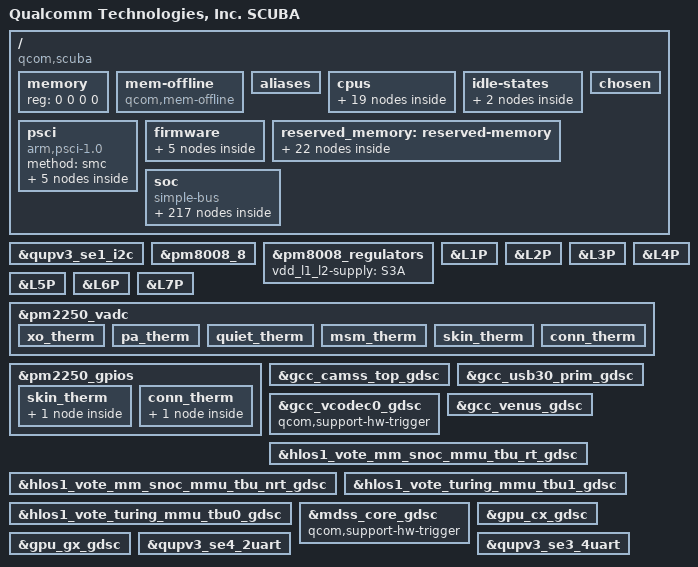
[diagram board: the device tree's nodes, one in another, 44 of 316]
#include <dt-bindings/interrupt-controller/arm-gic.h>
#include <dt-bindings/interconnect/qcom,icc.h>
#include <dt-bindings/interconnect/qcom,scuba.h>
#include <dt-bindings/clock/qcom,dispcc-scuba.h>
#include <dt-bindings/clock/qcom,gcc-scuba.h>
#include <dt-bindings/clock/qcom,gpucc-scuba.h>
#include <dt-bindings/spmi/spmi.h>
#include <dt-bindings/clock/qcom,rpmcc.h>
#include <dt-bindings/regulator/qcom,rpmh-regulator-levels.h>
#include <dt-bindings/gpio/gpio.h>
#include <dt-bindings/soc/qcom,dcc_v2.h>

/ {
	model = "Qualcomm Technologies, Inc. SCUBA";
	compatible = "qcom,scuba";
	qcom,msm-id = <441 0x10000>;
	interrupt-parent = <&intc>;

	#address-cells = <2>;
	#size-cells = <2>;
	memory { device_type = "memory"; reg = <0 0 0 0>; };

	mem-offline {
		compatible = "qcom,mem-offline";
		offline-sizes = <0x1 0x40000000 0x0 0x40000000>,
				<0x1 0xc0000000 0x0 0x80000000>,
				<0x2 0xc0000000 0x1 0x40000000>;
		granule = <512>;
	};

	aliases: aliases {
		mmc0 = &sdhc_1; /* SDC1 eMMC slot */
		mmc1 = &sdhc_2; /* SDC2 SD Card slot */
		serial0 = &qupv3_se4_2uart;
		hsuart0 = &qupv3_se3_4uart;
	};

	cpus {
		#address-cells = <2>;
		#size-cells = <0>;

		CPU0: cpu@0 {
			device_type = "cpu";
			compatible = "arm,armv8";
			reg = <0x0 0x0>;
			cpu-idle-states = <&SILVER_OFF>;
			power-domains = <&CPU_PD0>;
			power-domain-names = "psci";
			enable-method = "psci";
			capacity-dmips-mhz = <1024>;
			dynamic-power-coefficient = <100>;
			next-level-cache = <&L2_0>;
			qcom,freq-domain = <&cpufreq_hw 0 4>;
			qcom,lmh-dcvs = <&lmh_dcvs0>;
			#cooling-cells = <2>;
			L2_0: l2-cache {
				compatible = "arm,arch-cache";
				cache-level = <2>;
			};

			L1_I_0: l1-icache {
				compatible = "arm,arch-cache";
			};

			L1_D_0: l1-dcache {
				compatible = "arm,arch-cache";
			};
		};

		CPU1: cpu@1 {
			device_type = "cpu";
			compatible = "arm,armv8";
			reg = <0x0 0x1>;
			cpu-idle-states = <&SILVER_OFF>;
			power-domains = <&CPU_PD1>;
			power-domain-names = "psci";
			enable-method = "psci";
			capacity-dmips-mhz = <1024>;
			dynamic-power-coefficient = <100>;
			next-level-cache = <&L2_0>;
			qcom,freq-domain = <&cpufreq_hw 0 4>;
			qcom,lmh-dcvs = <&lmh_dcvs0>;

			L1_I_1: l1-icache {
				compatible = "arm,arch-cache";
			};

			L1_D_1: l1-dcache {
				compatible = "arm,arch-cache";
			};
		};

		CPU2: cpu@2 {
			device_type = "cpu";
			compatible = "arm,armv8";
			reg = <0x0 0x2>;
			cpu-idle-states = <&SILVER_OFF>;
			power-domains = <&CPU_PD2>;
			power-domain-names = "psci";
			enable-method = "psci";
			capacity-dmips-mhz = <1024>;
			dynamic-power-coefficient = <100>;
			next-level-cache = <&L2_0>;
			qcom,freq-domain = <&cpufreq_hw 0 4>;
			qcom,lmh-dcvs = <&lmh_dcvs0>;

			L1_I_2: l1-icache {
				compatible = "arm,arch-cache";
			};

			L1_D_2: l1-dcache {
				compatible = "arm,arch-cache";
			};
		};

		CPU3: cpu@3 {
			device_type = "cpu";
			compatible = "arm,armv8";
			reg = <0x0 0x3>;
			cpu-idle-states = <&SILVER_OFF>;
			power-domains = <&CPU_PD3>;
			power-domain-names = "psci";
			enable-method = "psci";
			capacity-dmips-mhz = <1024>;
			dynamic-power-coefficient = <100>;
			next-level-cache = <&L2_0>;
			qcom,freq-domain = <&cpufreq_hw 0 4>;
			qcom,lmh-dcvs = <&lmh_dcvs0>;

			L1_I_3: l1-icache {
				compatible = "arm,arch-cache";
			};

			L1_D_3: l1-dcache {
				compatible = "arm,arch-cache";
			};
		};

		cpu-map {
			cluster0 {
				core0 {
					cpu = <&CPU0>;
				};

				core1 {
					cpu = <&CPU1>;
				};

				core2 {
					cpu = <&CPU2>;
				};

				core3 {
					cpu = <&CPU3>;
				};
			};
		};
	};

	idle-states {
		SILVER_OFF: silver-c3 {  /* C3 */
			compatible = "arm,idle-state";
			idle-state-name = "pc";
			entry-latency-us = <297>;
			exit-latency-us = <324>;
			min-residency-us = <1110>;
			arm,psci-suspend-param = <0x40000003>;
			local-timer-stop;
		};

		SILVER_CLUSTER_D3: silver-cluster-d3 { /* D3 */
			compatible = "domain-idle-state";
			idle-state-name = "pwr-l2-pc";
			entry-latency-us = <800>;
			exit-latency-us = <2118>;
			min-residency-us = <7376>;
			arm,psci-suspend-param = <0x41000043>;
		};
	};

	psci {
		compatible = "arm,psci-1.0";
		method = "smc";

		CPU_PD0: cpu-pd0 {
			#power-domain-cells = <0>;
			power-domains = <&CLUSTER_PD>;
		};

		CPU_PD1: cpu-pd1 {
			#power-domain-cells = <0>;
			power-domains = <&CLUSTER_PD>;
		};

		CPU_PD2: cpu-pd2 {
			#power-domain-cells = <0>;
			power-domains = <&CLUSTER_PD>;
		};

		CPU_PD3: cpu-pd3 {
			#power-domain-cells = <0>;
			power-domains = <&CLUSTER_PD>;
		};

		CLUSTER_PD: cluster-pd0 {
			#power-domain-cells = <0>;
			domain-idle-states = <&SILVER_CLUSTER_D3>;
		};
	};

	firmware: firmware {
		qcom_scm {
			compatible = "qcom,scm";
			qcom,dload-mode = <&tcsr 0x13000>;
		};

		android {
			compatible = "android,firmware";
			vbmeta {
				compatible="android,vbmeta";
				parts = "vbmeta,boot,system,vendor,dtbo,recovery";
			};

			fstab {
				compatible = "android,fstab";
				vendor {
					compatible = "android,vendor";
					dev = "/dev/block/platform/soc/4744000.sdhci/by-name/vendor";
					type = "ext4";
					mnt_flags = "ro,barrier=1,discard";
					fsmgr_flags = "wait,slotselect,avb";
					status = "ok";
				};
			};
		};
	};

	reserved_memory: reserved-memory {
		#address-cells = <2>;
		#size-cells = <2>;
		ranges;

		hyp_region: hyp_region@45700000 {
			no-map;
			reg = <0x0 0x45700000 0x0 0x600000>;
		};

		xbl_aop_mem: xbl_aop_mem@45e00000 {
			no-map;
			reg = <0x0 0x45e00000 0x0 0x100000>;
		};

		sec_apps_mem: sec_apps_region@45fff000 {
			no-map;
			reg = <0x0 0x45fff000 0x0 0x1000>;
		};

		smem_region: smem@46000000 {
			no-map;
			reg = <0x0 0x46000000 0x0 0x200000>;
		};

		pil_modem_mem: modem_region@4ab00000 {
			no-map;
			reg = <0x0 0x4ab00000 0x0 0x6900000>;
		};

		wlan_msa_mem: wlan_msa_region@51900000 {
			no-map;
			reg = <0x0 0x51900000 0x0 0x100000>;
		};

		pil_adsp_mem: adsp_regions@51a00000 {
			no-map;
			reg = <0x0 0x51a00000 0x0 0x1c00000>;
		};

		pil_ipa_fw_mem: ips_fw_region@53600000 {
			no-map;
			reg = <0x0 0x53600000 0x0 0x10000>;
		};

		pil_ipa_gsi_mem: ipa_gsi_region@53610000 {
			no-map;
			reg = <0x0 0x53610000 0x0 0x5000>;
		};

		pil_gpu_mem: gpu_region@53615000 {
			no-map;
			reg = <0x0 0x53615000 0x0 0x2000>;
		};

		video_mem: video_region@53617000 {
			no-map;
			reg = <0x0 0x53617000 0x0 0x700000>;
		};

		removed_region: removed_region@60000000 {
			no-map;
			reg = <0x0 0x60000000 0x0 0x3900000>;
		};

		adsp_mem: adsp_region {
			compatible = "shared-dma-pool";
			alloc-ranges = <0 0x00000000 0 0xffffffff>;
			reusable;
			alignment = <0 0x400000>;
			size = <0 0x800000>;
		};

		dump_mem: mem_dump_region {
			compatible = "shared-dma-pool";
			alloc-ranges = <0x0 0x00000000 0x0 0xffffffff>;
			reusable;
			size = <0 0x800000>;
		};

		secure_display_memory: secure_display_region {
			compatible = "shared-dma-pool";
			alloc-ranges = <0 0x00000000 0 0xffffffff>;
			reusable;
			alignment = <0 0x400000>;
			size = <0 0x5c00000>;
		};

		non_secure_display_memory: non_secure_display_region {
			compatible = "shared-dma-pool";
			reusable;
			alloc-ranges = <0x0 0x00000000 0x0 0xffffffff>;
			size = <0x0 0xa400000>;
			alignment = <0x0 0x400000>;
		};

		qseecom_mem: qseecom_region {
			compatible = "shared-dma-pool";
			alloc-ranges = <0x0 0x00000000 0x0 0xffffffff>;
			reusable;
			alignment = <0x0 0x400000>;
			size = <0x0 0x1400000>;
		};

		qseecom_ta_mem: qseecom_ta_region {
			compatible = "shared-dma-pool";
			alloc-ranges = <0x0 0x00000000 0x0 0xffffffff>;
			reusable;
			alignment = <0x0 0x400000>;
			size = <0x0 0x1000000>;
		};

		ramoops_mem: ramoops_region {
			compatible = "ramoops";
			alloc-ranges = <0x0 0x00000000 0xffffffff 0xffffffff>;
			size = <0x0 0x200000>;
			pmsg-size = <0x200000>;
			mem-type = <2>;
		};

		audio_cma_mem: audio_cma_region {
			compatible = "shared-dma-pool";
			alloc-ranges = <0x0 0x00000000 0x0 0xffffffff>;
			reusable;
			alignment = <0x0 0x400000>;
			size = <0x0 0x1C00000>;
		};

		/* global autoconfigured region for contiguous allocations */
		system_cma: linux,cma {
			compatible = "shared-dma-pool";
			alloc-ranges = <0x0 0x00000000 0x0 0xffffffff>;
			reusable;
			alignment = <0x0 0x400000>;
			size = <0x0 0x2000000>;
			linux,cma-default;
		};

		va_md_mem: va_md_mem_region {
			compatible = "shared-dma-pool";
			alloc-ranges = <0x0 0x00000000 0x0 0xffffffff>;
			reusable;
			size = <0x0 0x1000000>;
		};
	};

	chosen {
		bootargs = "lpm_levels.sleep_disabled=1 console=ttyMSM0,115200n8 msm_rtb.filter=0x237 service_locator.enable=1 swiotlb=2048 loop.max_part=7 cpufreq.default_governor=performance rcupdate.rcu_expedited=1 rcu_nocbs=0-7 kpti=off export_pmu_events movable_node ftrace_dump_on_oops disable_dma32=on cgroup.memory=nokmem,nosocket panic=5";
	};

	soc: soc { };
};

&soc {
	#address-cells = <1>;
	#size-cells = <1>;
	ranges = <0 0 0 0xffffffff>;
	compatible = "simple-bus";

	slimbam: bamdma@a584000 {
		compatible = "qcom,bam-v1.7.0";
		reg = <0xa584000 0x20000>, <0xa66f000 0x1000>;
		reg-names = "bam", "bam_remote_mem";
		#dma-cells = <1>;
		interrupts = <GIC_SPI 284 IRQ_TYPE_LEVEL_HIGH>;
		qcom,controlled-remotely;
		num-channels  = <31>;
		qcom,ee = <1>;
		qcom,num-ees = <2>;
	};

	slim_msm: slim@a5c0000 {
		compatible = "qcom,slim-ngd-v1.5.0";
		reg = <0xa5c0000 0x2c000>, <0xa66e000 0x1000>;
		reg-names = "ctrl", "slimbus_remote_mem";
		#address-cells = <1>;
		#size-cells = <0>;
		interrupts = <GIC_SPI 283 IRQ_TYPE_LEVEL_HIGH>;
		qcom,apps-ch-pipes = <0x0>;
		qcom,ea-pc = <0x360>;
		dmas = <&slimbam 3>, <&slimbam 4>;
		dma-names = "rx", "tx";
		status = "disabled";
	};

	intc: interrupt-controller@f200000 {
		compatible = "arm,gic-v3";
		#interrupt-cells = <3>;
		interrupt-controller;
		interrupt-parent = <&intc>;
		#redistributor-regions = <1>;
		redistributor-stride = <0x0 0x20000>;
		reg = <0xf200000 0x10000>,     /* GICD */
		      <0xf300000 0x100000>;    /* GICR * 8 */
		interrupts = <1 9 4>;
	};

	mpm: interrupt-controller@0x45f01b8 {
		compatible = "qcom,mpm", "qcom,mpm-scuba";
		interrupts = <GIC_SPI 197 IRQ_TYPE_EDGE_RISING>;
		reg = <0x45f01b8 0x1000>,
		      <0xf111008 0x4>,  /* MSM_APCS_GCC_BASE 4K */
		      <0xf121000 0x1000>;
		reg-names = "vmpm", "ipc", "timer";
		qcom,num-mpm-irqs = <96>;
		interrupt-controller;
		interrupt-parent = <&intc>;
		#interrupt-cells = <2>;
	};

	jtag_mm0: jtagmm@9040000 {
		compatible = "qcom,jtagv8-mm";
		reg = <0x9040000 0x1000>;
		reg-names = "etm-base";

		clocks = <&rpmcc RPM_SMD_QDSS_CLK>;
		clock-names = "core_clk";

		qcom,coresight-jtagmm-cpu = <&CPU0>;
	};

	jtag_mm1: jtagmm@9140000 {
		compatible = "qcom,jtagv8-mm";
		reg = <0x9140000 0x1000>;
		reg-names = "etm-base";

		clocks = <&rpmcc RPM_SMD_QDSS_CLK>;
		clock-names = "core_clk";

		qcom,coresight-jtagmm-cpu = <&CPU1>;
	};

	jtag_mm2: jtagmm@9240000 {
		compatible = "qcom,jtagv8-mm";
		reg = <0x9240000 0x1000>;
		reg-names = "etm-base";

		clocks = <&rpmcc RPM_SMD_QDSS_CLK>;
		clock-names = "core_clk";

		qcom,coresight-jtagmm-cpu = <&CPU2>;
	};

	jtag_mm3: jtagmm@9340000 {
		compatible = "qcom,jtagv8-mm";
		reg = <0x9340000 0x1000>;
		reg-names = "etm-base";

		clocks = <&rpmcc RPM_SMD_QDSS_CLK>;
		clock-names = "core_clk";

		qcom,coresight-jtagmm-cpu = <&CPU3>;
	};

	timer {
		compatible = "arm,armv8-timer";
		interrupts = <1 1 0xf08>,
			     <1 2 0xf08>,
			     <1 3 0xf08>,
			     <1 0 0xf08>;
		clock-frequency = <19200000>;
	};

	dcc: dcc_v2@1be2000 {
		compatible = "qcom,dcc-v2";
		reg = <0x1be2000 0x1000>,
			<0x1bee000 0x2000>;
		reg-names = "dcc-base", "dcc-ram-base";
		dcc-ram-offset = <0x2000>;

		link_list1 {
			qcom,curr-link-list = <3>;
			qcom,data-sink = "sram";
			qcom,link-list = <DCC_READ 0x0f1880b4 1 0>,
				<DCC_READ 0x0f1980b4 1 0>,
				<DCC_READ 0x0f1a80b4 1 0>,
				<DCC_READ 0x0f1b80b4 1 0>,
				<DCC_READ 0x0f1d1228 1 0>,
				<DCC_READ 0x4488100 1 0>,
				<DCC_READ 0x4488400 2 0>,
				<DCC_READ 0x4488410 1 0>,
				<DCC_READ 0x4488420 2 0>,
				<DCC_READ 0x4488430 2 0>,
				<DCC_READ 0x448c100 1 0>,
				<DCC_READ 0x448c400 2 0>,
				<DCC_READ 0x448c410 1 0>,
				<DCC_READ 0x448c420 2 0>,
				<DCC_READ 0x448c430 2 0>,
				<DCC_READ 0x4490100 1 0>,
				<DCC_READ 0x4490400 2 0>,
				<DCC_READ 0x4490410 1 0>,
				<DCC_READ 0x4490420 2 0>,
				<DCC_READ 0x4490430 2 0>,
				<DCC_READ 0x4494100 1 0>,
				<DCC_READ 0x4494400 2 0>,
				<DCC_READ 0x4494410 1 0>,
				<DCC_READ 0x4494420 2 0>,
				<DCC_READ 0x4494430 2 0>,
				<DCC_READ 0x449810c 1 0>,
				<DCC_READ 0x4498400 2 0>,
				<DCC_READ 0x4498410 1 0>,
				<DCC_READ 0x4498420 2 0>,
				<DCC_READ 0x4498430 2 0>,
				<DCC_READ 0x44a0100 1 0>,
				<DCC_READ 0x44a0400 2 0>,
				<DCC_READ 0x44a0410 1 0>,
				<DCC_READ 0x44a0420 2 0>,
				<DCC_READ 0x44a0430 2 0>,
				<DCC_READ 0x44b0560 1 0>,
				<DCC_READ 0x44b05a0 1 0>,
				<DCC_READ 0x44b1800 1 0>,
				<DCC_READ 0x44b408c 1 0>,
				<DCC_READ 0x44b409c 1 0>,
				<DCC_READ 0x44b0520 1 0>,
				<DCC_READ 0x44b5070 2 0>,
				<DCC_READ 0x44bc220 1 0>,
				<DCC_READ 0x44bc400 7 0>,
				<DCC_READ 0x44bc420 9 0>,
				<DCC_READ 0x44bd800 1 0>,
				<DCC_READ 0x44c5800 1 0>,
				<DCC_READ 0x4480040 2 0>,
				<DCC_READ 0x4480810 2 0>,
				<DCC_READ 0x44b0a40 1 0>,
				<DCC_READ 0x4506044 1 0>,
				<DCC_READ 0x45061dc 1 0>,
				<DCC_READ 0x45061ec 1 0>,
				<DCC_READ 0x4506028 2 0>,
				<DCC_READ 0x4506094 1 0>,
				<DCC_READ 0x4506608 1 0>,
				<DCC_READ 0x447d02c 4 0>,
				<DCC_READ 0x447d040 1 0>,
				<DCC_READ 0x450002c 2 0>,
				<DCC_READ 0x4500094 1 0>,
				<DCC_READ 0x450009c 1 0>,
				<DCC_READ 0x45000c4 2 0>,
				<DCC_READ 0x45003dc 1 0>,
				<DCC_READ 0x45005d8 1 0>,
				<DCC_READ 0x450102c 2 0>,
				<DCC_READ 0x4501094 1 0>,
				<DCC_READ 0x450109c 1 0>,
				<DCC_READ 0x45010c4 2 0>,
				<DCC_READ 0x45013dc 1 0>,
				<DCC_READ 0x45015d8 1 0>,
				<DCC_READ 0x450202c 2 0>,
				<DCC_READ 0x4502094 1 0>,
				<DCC_READ 0x450209c 1 0>,
				<DCC_READ 0x45020c4 2 0>,
				<DCC_READ 0x45023dc 1 0>,
				<DCC_READ 0x45025d8 1 0>,
				<DCC_READ 0x450302c 2 0>,
				<DCC_READ 0x4503094 1 0>,
				<DCC_READ 0x450309c 1 0>,
				<DCC_READ 0x45030c4 2 0>,
				<DCC_READ 0x45033dc 1 0>,
				<DCC_READ 0x45035d8 1 0>,
				<DCC_READ 0x450402c 2 0>,
				<DCC_READ 0x4504094 1 0>,
				<DCC_READ 0x450409c 1 0>,
				<DCC_READ 0x45040c8 2 0>,
				<DCC_READ 0x45043dc 1 0>,
				<DCC_READ 0x45045d8 1 0>,
				<DCC_READ 0x450502c 2 0>,
				<DCC_READ 0x4505094 1 0>,
				<DCC_READ 0x450509c 1 0>,
				<DCC_READ 0x45050c4 2 0>,
				<DCC_READ 0x45053dc 1 0>,
				<DCC_READ 0x45055d8 1 0>,
				<DCC_READ 0x1900010 1 0>,
				<DCC_READ 0x1900020 1 0>,
				<DCC_READ 0x1900024 1 0>,
				<DCC_READ 0x1900028 1 0>,
				<DCC_READ 0x190002c 1 0>,
				<DCC_READ 0x1900030 1 0>,
				<DCC_READ 0x1900034 1 0>,
				<DCC_READ 0x1900038 1 0>,
				<DCC_READ 0x190003c 1 0>,
				<DCC_READ 0x1900240 1 0>,
				<DCC_READ 0x1900244 1 0>,
				<DCC_READ 0x1900248 1 0>,
				<DCC_READ 0x190024c 1 0>,
				<DCC_READ 0x1900250 1 0>,
				<DCC_READ 0x1900258 1 0>,
				<DCC_READ 0x1900290 1 0>,
				<DCC_READ 0x1900300 1 0>,
				<DCC_READ 0x1900304 1 0>,
				<DCC_READ 0x1900308 1 0>,
				<DCC_READ 0x190030c 1 0>,
				<DCC_READ 0x1900310 1 0>,
				<DCC_READ 0x1900314 1 0>,
				<DCC_READ 0x1900318 1 0>,
				<DCC_READ 0x1900900 1 0>,
				<DCC_READ 0x1900904 1 0>,
				<DCC_READ 0x1900d00 1 0>,
				<DCC_READ 0x1909100 1 0>,
				<DCC_READ 0x1909104 1 0>,
				<DCC_READ 0x44b0120 1 0>,
				<DCC_READ 0x44b0124 1 0>,
				<DCC_READ 0x44b0128 1 0>,
				<DCC_READ 0x44b012c 1 0>,
				<DCC_READ 0x44b0130 1 0>,
				<DCC_READ 0x44b0100 1 0>,
				<DCC_READ 0x44b0020 1 0>,
				<DCC_READ 0x44c4000 1 0>,
				<DCC_READ 0x44c4020 1 0>,
				<DCC_READ 0x44c4030 1 0>,
				<DCC_READ 0x44c4100 1 0>,
				<DCC_READ 0x44c410c 1 0>,
				<DCC_READ 0x44c4400 1 0>,
				<DCC_READ 0x44c4410 1 0>,
				<DCC_READ 0x44c4420 1 0>,
				<DCC_READ 0x1411004 1 0>,
				<DCC_READ 0x1411028 1 0>,
				<DCC_READ 0x1458004 1 0>,
				<DCC_READ 0x1880108 1 0>,
				<DCC_READ 0x1880110 1 0>,
				<DCC_READ 0x1880120 1 0>,
				<DCC_READ 0x1880124 1 0>,
				<DCC_READ 0x1880128 1 0>,
				<DCC_READ 0x188012c 1 0>,
				<DCC_READ 0x1880130 1 0>,
				<DCC_READ 0x1880134 1 0>,
				<DCC_READ 0x1880138 1 0>,
				<DCC_READ 0x188013c 1 0>,
				<DCC_READ 0x1880240 1 0>,
				<DCC_READ 0x1880248 1 0>,
				<DCC_READ 0x1880290 1 0>,
				<DCC_READ 0x1880300 1 0>,
				<DCC_READ 0x1880304 1 0>,
				<DCC_READ 0x1880308 1 0>,
				<DCC_READ 0x188030c 1 0>,
				<DCC_READ 0x1880310 1 0>,
				<DCC_READ 0x1880314 1 0>,
				<DCC_READ 0x1880318 1 0>,
				<DCC_READ 0x188031c 1 0>,
				<DCC_READ 0x1880700 1 0>,
				<DCC_READ 0x1880704 1 0>,
				<DCC_READ 0x1880708 1 0>,
				<DCC_READ 0x188070c 1 0>,
				<DCC_READ 0x1880710 1 0>,
				<DCC_READ 0x1880714 1 0>,
				<DCC_READ 0x1880718 1 0>,
				<DCC_READ 0x188071c 1 0>,
				<DCC_READ 0x1881100 1 0>,
				<DCC_READ 0x1881104 1 0>,
				<DCC_READ 0xf112000 1 0>,
				<DCC_READ 0xf11200c 1 0>,
				<DCC_READ 0xf112c0c 1 0>,
				<DCC_READ 0xf112c10 1 0>,
				<DCC_READ 0xf112c20 1 0>,
				<DCC_READ 0xf1b9000 1 0>,
				<DCC_READ 0xf1b900c 1 0>,
				<DCC_READ 0xf1b9c0c 1 0>,
				<DCC_READ 0xf1b9c10 1 0>,
				<DCC_READ 0xf1b9c18 1 0>,
				<DCC_READ 0xf1a9000 1 0>,
				<DCC_READ 0xf1a900c 1 0>,
				<DCC_READ 0xf1a9c0c 1 0>,
				<DCC_READ 0xf1a9c10 1 0>,
				<DCC_READ 0xf1a9c20 1 0>,
				<DCC_READ 0xf199000 1 0>,
				<DCC_READ 0xf19900c 1 0>,
				<DCC_READ 0xf199c0c 1 0>,
				<DCC_READ 0xf199c10 1 0>,
				<DCC_READ 0xf199c20 1 0>,
				<DCC_READ 0xf189000 1 0>,
				<DCC_READ 0xf18900c 1 0>,
				<DCC_READ 0xf189c0c 1 0>,
				<DCC_READ 0xf189c10 1 0>,
				<DCC_READ 0xf189c20 1 0>,
				<DCC_READ 0xf111014 1 0>,
				<DCC_READ 0xf111018 1 0>,
				<DCC_READ 0xf111218 1 0>,
				<DCC_READ 0xf111234 1 0>,
				<DCC_READ 0xf111264 1 0>,
				<DCC_READ 0xf111290 1 0>,
				<DCC_READ 0x0f521700 1 0>,
				<DCC_READ 0x0f112c18 1 0>,
				<DCC_READ 0x0f513a84 1 0>,
				<DCC_READ 0x01b60110 1 0>,
				<DCC_READ 0x1400000 1 0>,
				<DCC_READ 0x1400004 1 0>,
				<DCC_READ 0x1400008 1 0>,
				<DCC_READ 0x1400010 1 0>,
				<DCC_READ 0x1400014 1 0>,
				<DCC_READ 0x1400018 1 0>,
				<DCC_READ 0x1400020 1 0>,
				<DCC_READ 0x1400024 1 0>,
				<DCC_READ 0x1401000 1 0>,
				<DCC_READ 0x1401004 1 0>,
				<DCC_READ 0x1401008 1 0>,
				<DCC_READ 0x1401010 1 0>,
				<DCC_READ 0x1401014 1 0>,
				<DCC_READ 0x1401018 1 0>,
				<DCC_READ 0x1401020 1 0>,
				<DCC_READ 0x1401024 1 0>,
				<DCC_READ 0x1402000 1 0>,
				<DCC_READ 0x1402004 1 0>,
				<DCC_READ 0x1402008 1 0>,
				<DCC_READ 0x1402010 1 0>,
				<DCC_READ 0x1402014 1 0>,
				<DCC_READ 0x1402018 1 0>,
				<DCC_READ 0x1402020 1 0>,
				<DCC_READ 0x1402024 1 0>,
				<DCC_READ 0x1403000 1 0>,
				<DCC_READ 0x1403004 1 0>,
				<DCC_READ 0x1403008 1 0>,
				<DCC_READ 0x1403010 1 0>,
				<DCC_READ 0x1403014 1 0>,
				<DCC_READ 0x1403018 1 0>,
				<DCC_READ 0x1403020 1 0>,
				<DCC_READ 0x1403024 1 0>,
				<DCC_READ 0x1404000 1 0>,
				<DCC_READ 0x1404004 1 0>,
				<DCC_READ 0x1404008 1 0>,
				<DCC_READ 0x1404010 1 0>,
				<DCC_READ 0x1404014 1 0>,
				<DCC_READ 0x1404018 1 0>,
				<DCC_READ 0x1404020 1 0>,
				<DCC_READ 0x1404024 1 0>,
				<DCC_READ 0x1405000 1 0>,
				<DCC_READ 0x1405004 1 0>,
				<DCC_READ 0x1405008 1 0>,
				<DCC_READ 0x1405010 1 0>,
				<DCC_READ 0x1405014 1 0>,
				<DCC_READ 0x1405018 1 0>,
				<DCC_READ 0x1405020 1 0>,
				<DCC_READ 0x1405024 1 0>,
				<DCC_READ 0x1406000 1 0>,
				<DCC_READ 0x1406004 1 0>,
				<DCC_READ 0x1406008 1 0>,
				<DCC_READ 0x1406010 1 0>,
				<DCC_READ 0x1406014 1 0>,
				<DCC_READ 0x1406018 1 0>,
				<DCC_READ 0x1406020 1 0>,
				<DCC_READ 0x1406024 1 0>,
				<DCC_READ 0x1407000 1 0>,
				<DCC_READ 0x1407004 1 0>,
				<DCC_READ 0x1407008 1 0>,
				<DCC_READ 0x1407010 1 0>,
				<DCC_READ 0x1407014 1 0>,
				<DCC_READ 0x1407018 1 0>,
				<DCC_READ 0x1407020 1 0>,
				<DCC_READ 0x1407024 1 0>,
				<DCC_READ 0x1407028 1 0>,
				<DCC_READ 0x1408000 1 0>,
				<DCC_READ 0x1408004 1 0>,
				<DCC_READ 0x1408008 1 0>,
				<DCC_READ 0x1408010 1 0>,
				<DCC_READ 0x1408014 1 0>,
				<DCC_READ 0x1408018 1 0>,
				<DCC_READ 0x1408020 1 0>,
				<DCC_READ 0x1408024 1 0>,
				<DCC_READ 0x1409000 1 0>,
				<DCC_READ 0x1409004 1 0>,
				<DCC_READ 0x1409008 1 0>,
				<DCC_READ 0x1409010 1 0>,
				<DCC_READ 0x1409014 1 0>,
				<DCC_READ 0x1409018 1 0>,
				<DCC_READ 0x1409020 1 0>,
				<DCC_READ 0x1414024 1 0>,
				<DCC_READ 0x1416038 1 0>,
				<DCC_READ 0x1415034 1 0>,
				<DCC_READ 0x1417040 1 0>,
				<DCC_READ 0x1420010 1 0>,
				<DCC_READ 0x1420014 1 0>,
				<DCC_READ 0x1426018 1 0>,
				<DCC_READ 0x1426030 1 0>,
				<DCC_READ 0x1426034 1 0>,
				<DCC_READ 0x1427024 1 0>,
				<DCC_READ 0x1428014 1 0>,
				<DCC_READ 0x1428018 1 0>,
				<DCC_READ 0x1428030 1 0>,
				<DCC_READ 0x1429004 1 0>,
				<DCC_READ 0x1429008 1 0>,
				<DCC_READ 0x1429040 1 0>,
				<DCC_READ 0x1429044 1 0>,
				<DCC_READ 0x1446004 1 0>,
				<DCC_READ 0x1446008 1 0>,
				<DCC_READ 0x1446024 1 0>,
				<DCC_READ 0x1446150 1 0>,
				<DCC_READ 0x1442018 1 0>,
				<DCC_READ 0x1442030 1 0>,
				<DCC_READ 0x1442034 1 0>,
				<DCC_READ 0x1432034 1 0>,
				<DCC_READ 0x1438010 1 0>,
				<DCC_READ 0x1438014 1 0>,
				<DCC_READ 0x1438028 1 0>,
				<DCC_READ 0x1445004 1 0>,
				<DCC_READ 0x1445020 1 0>,
				<DCC_READ 0x1451000 1 0>,
				<DCC_READ 0x1451004 1 0>,
				<DCC_READ 0x1451020 1 0>,
				<DCC_READ 0x1451038 1 0>,
				<DCC_READ 0x1451054 1 0>,
				<DCC_READ 0x1451058 1 0>,
				<DCC_READ 0x1452004 1 0>,
				<DCC_READ 0x1452008 1 0>,
				<DCC_READ 0x1452028 1 0>,
				<DCC_READ 0x1455000 1 0>,
				<DCC_READ 0x1455004 1 0>,
				<DCC_READ 0x1448024 1 0>,
				<DCC_READ 0x1475000 1 0>,
				<DCC_READ 0x1475004 1 0>,
				<DCC_READ 0x1477000 1 0>,
				<DCC_READ 0x1477004 1 0>,
				<DCC_READ 0x1479000 1 0>,
				<DCC_READ 0x1479004 1 0>,
				<DCC_READ 0x1457000 1 0>,
				<DCC_READ 0x1457004 1 0>,
				<DCC_READ 0x1457008 1 0>,
				<DCC_READ 0x1457010 1 0>,
				<DCC_READ 0x1469000 1 0>,
				<DCC_READ 0x1469004 1 0>,
				<DCC_READ 0x1469008 1 0>,
				<DCC_READ 0x1469010 1 0>,
				<DCC_READ 0x1495000 1 0>,
				<DCC_READ 0x1495004 1 0>,
				<DCC_READ 0x1463020 1 0>,
				<DCC_READ 0x1478030 1 0>,
				<DCC_READ 0x1490004 1 0>,
				<DCC_READ 0x1490008 1 0>,
				<DCC_READ 0x1490024 1 0>,
				<DCC_READ 0x1490028 1 0>,
				<DCC_READ 0x1407030 1 0>,
				<DCC_READ 0x1407034 1 0>,
				<DCC_READ 0x1432080 1 0>,
				<DCC_READ 0xf017000 1 0>,
				<DCC_READ 0xf01700c 1 0>,
				<DCC_READ 0xf017010 1 0>,
				<DCC_READ 0xf017014 1 0>,
				<DCC_READ 0xf017018 1 0>,
				<DCC_READ 0xf017020 1 0>,
				<DCC_READ 0x1414008 1 0>,
				<DCC_READ 0x1414004 1 0>,
				<DCC_READ 0x5991554 1 0>,
				<DCC_READ 0x5991544 1 0>,
				<DCC_READ 0x599155c 1 0>,
				<DCC_READ 0x440b00c 1 0>,
				<DCC_READ 0x440b014 1 0>,
				<DCC_READ 0x0f522c14 1 0>,
				<DCC_READ 0x0f522c1c 1 0>,
				<DCC_READ 0x0f522c10 1 0>,
				<DCC_READ 0x0f521920 1 0>,
				<DCC_READ 0x0f52102c 1 0>,
				<DCC_READ 0x0f521044 1 0>,
				<DCC_READ 0x0f521710 1 0>,
				<DCC_READ 0x0f52176c 1 0>,
				<DCC_READ 0x0f116000 1 0>,
				<DCC_READ 0x0f116004 1 0>,
				<DCC_READ 0x0f11602c 1 0>,
				<DCC_READ 0x0f111250 1 0>,
				<DCC_READ 0x0f111254 1 0>,
				<DCC_READ 0x0f111258 1 0>,
				<DCC_READ 0x0f11125c 1 0>,
				<DCC_READ 0x0f111260 1 0>,
				<DCC_READ 0x0f188078 1 0>,
				<DCC_READ 0x0f188084 1 0>,
				<DCC_READ 0x0f198078 1 0>,
				<DCC_READ 0x0f198084 1 0>,
				<DCC_READ 0x0f1a8078 1 0>,
				<DCC_READ 0x0f1a8084 1 0>,
				<DCC_READ 0x0f1b8078 1 0>,
				<DCC_READ 0x0f1b8084 1 0>,
				<DCC_READ 0x0f521818 1 0>,
				<DCC_READ 0x0f52181c 1 0>,
				<DCC_READ 0x0f521828 1 0>,
				<DCC_READ 0x0f522c18 1 0>,
				<DCC_READ 0x0f111310 1 0>,
				<DCC_READ 0x0f111314 1 0>,
				<DCC_READ 0x0f111318 1 0>,
				<DCC_WRITE 0x9870010 0x14000 1>,
				<DCC_WRITE 0x9870010 0x0 1>,
				<DCC_READ 0x5c6f000 1 0>,
				<DCC_READ 0x5c42000 1 0>,
				<DCC_READ 0x5c42400 1 0>,
				<DCC_READ 0x5c23000 1 0>;
		};
	};

	timer@f120000 {
		#address-cells = <1>;
		#size-cells = <1>;
		ranges;
		compatible = "arm,armv7-timer-mem";
		reg = <0xf120000 0x1000>;
		clock-frequency = <19200000>;

		frame@f121000 {
			frame-number = <0>;
			interrupts = <0 8 0x4>,
				     <0 7 0x4>;
			reg = <0xf121000 0x1000>,
			      <0xf122000 0x1000>;
		};

		frame@f123000 {
			frame-number = <1>;
			interrupts = <0 9 0x4>;
			reg = <0xf123000 0x1000>;
			status = "disabled";
		};

		frame@f124000 {
			frame-number = <2>;
			interrupts = <0 10 0x4>;
			reg = <0xf124000 0x1000>;
			status = "disabled";
		};

		frame@f125000 {
			frame-number = <3>;
			interrupts = <0 11 0x4>;
			reg = <0xf125000 0x1000>;
			status = "disabled";
		};

		frame@f126000 {
			frame-number = <4>;
			interrupts = <0 12 0x4>;
			reg = <0xf126000 0x1000>;
			status = "disabled";
		};

		frame@f127000 {
			frame-number = <5>;
			interrupts = <0 13 0x4>;
			reg = <0xf127000 0x1000>;
			status = "disabled";
		};

		frame@f128000 {
			frame-number = <6>;
			interrupts = <0 14 0x4>;
			reg = <0xf128000 0x1000>;
			status = "disabled";
		};
	};

	arm64_cpu_erp {
		compatible = "arm,arm64-cpu-erp";
		interrupt-names = "pri-dbe-irq",
				  "pri-ext-irq";
		interrupts = <0 43 4>,
			     <0 41 4>;
		poll-delay-ms = <5000>;
	};

	vendor_hooks: qcom,cpu-vendor-hooks {
		compatible = "qcom,cpu-vendor-hooks";
	};

	qcom,msm-imem@c125000 {
		compatible = "qcom,msm-imem";
		reg = <0xc125000 0x1000>;
		ranges = <0x0 0xc125000 0x1000>;
		#address-cells = <1>;
		#size-cells = <1>;

		mem_dump_table@10 {
			compatible = "qcom,msm-imem-mem_dump_table";
			reg = <0x10 0x8>;
		};

		restart_reason@65c {
			compatible = "qcom,msm-imem-restart_reason";
			reg = <0x65c 0x4>;
		};

		dload_type@1c {
			compatible = "qcom,msm-imem-dload-type";
			reg = <0x1c 0x4>;
		};

		boot_stats@6b0 {
			compatible = "qcom,msm-imem-boot_stats";
			reg = <0x6b0 0x20>;
		};

		kaslr_offset@6d0 {
			compatible = "qcom,msm-imem-kaslr_offset";
			reg = <0x6d0 0xc>;
		};

		pil@94c {
			compatible = "qcom,msm-imem-pil";
			reg = <0x94c 0xc8>;
		};

		diag_dload@c8 {
			compatible = "qcom,msm-imem-diag-dload";
			reg = <0xc8 0xc8>;
		};
	};

	restart@440b000 {
		compatible = "qcom,pshold";
		reg = <0x440b000 0x4>,
		      <0x03d3000 0x4>;
		reg-names = "pshold-base", "tcsr-boot-misc-detect";
	};

	qcom_hwkm: hwkm@4440000 {
		compatible = "qcom,hwkm";
		reg = <0x4440000 0x9000>, <0x4750000 0x9000>;
		reg-names = "km_master", "ice_slave";
		qcom,enable-hwkm-clk;
		clock-names = "km_clk_src";
		clocks = <&rpmcc RPM_SMD_HWKM_CLK>;
		qcom,op-freq-hz = <75000000>;
	};

	qtee_shmbridge {
		compatible = "qcom,tee-shared-memory-bridge";
		qcom,disable-shmbridge-support;
	};

	qcom_seecom: qseecom@61800000 {
		compatible = "qcom,qseecom";
		reg = <0x61800000 0x2100000>;
		reg-names = "secapp-region";
		memory-region = <&qseecom_mem>;
		qcom,hlos-num-ce-hw-instances = <1>;
		qcom,hlos-ce-hw-instance = <0>;
		qcom,qsee-ce-hw-instance = <0>;
		qcom,disk-encrypt-pipe-pair = <2>;
		qcom,support-fde;
		qcom,fde-key-size;
		qcom,appsbl-qseecom-support;
		qcom,commonlib64-loaded-by-uefi;
		qcom,msm-bus,name = "qseecom-noc";
		qcom,msm-bus,num-cases = <4>;
		qcom,msm-bus,num-paths = <1>;
		qcom,ce-opp-freq = <192000000>;
		qcom,qsee-reentrancy-support = <2>;
		clock-names =
			"core_clk_src", "core_clk",
			"iface_clk", "bus_clk";
		clocks =
			<&rpmcc RPM_SMD_CE1_CLK>,
			<&rpmcc RPM_SMD_CE1_CLK>,
			<&rpmcc RPM_SMD_CE1_CLK>,
			<&rpmcc RPM_SMD_CE1_CLK>;
	};

	qcom_smcinvoke: smcinvoke@61800000 {
		compatible = "qcom,smcinvoke";
		qcom,support-legacy_smc;
		reg = <0x61800000 0x2100000>;
		reg-names = "secapp-region";
	};

	qcom_tzlog: tz-log@c125720 {
		compatible = "qcom,tz-log";
		reg = <0xc125720 0x3000>;
		qcom,hyplog-enabled;
		hyplog-address-offset = <0x410>;
		hyplog-size-offset = <0x414>;
	};

	qcom_rng: qrng@4453000 {
		compatible = "qcom,msm-rng";
		reg = <0x4453000 0x1000>;
		qcom,msm-rng-hwkm-clk;
		qcom,no-qrng-config;
		qcom,msm-bus,name = "msm-rng-noc";
		qcom,msm-bus,num-cases = <2>;
		qcom,msm-bus,num-paths = <1>;
		clock-names = "km_clk_src";
		clocks = <&rpmcc RPM_SMD_HWKM_CLK>;
	};

	qcom_cedev: qcedev@1b20000 {
		compatible = "qcom,qcedev";
		reg = <0x1b20000 0x20000>,
			<0x1b04000 0x24000>;
		reg-names = "crypto-base","crypto-bam-base";
		interrupts = <GIC_SPI 247 IRQ_TYPE_LEVEL_HIGH>;
		qcom,bam-pipe-pair = <3>;
		qcom,ce-hw-instance = <0>;
		qcom,ce-device = <0>;
		qcom,ce-hw-shared;
		qcom,bam-ee = <0>;
		qcom,msm-bus,name = "qcedev-noc";
		qcom,msm-bus,num-cases = <2>;
		qcom,msm-bus,num-paths = <1>;
		clock-names =
			 "core_clk_src", "core_clk",
			 "iface_clk", "bus_clk";
		clocks =
			 <&rpmcc RPM_SMD_CE1_CLK>,
			 <&rpmcc RPM_SMD_CE1_CLK>,
			 <&rpmcc RPM_SMD_CE1_CLK>,
			 <&rpmcc RPM_SMD_CE1_CLK>;
		qcom,ce-opp-freq = <192000000>;
		interconnect-names = "data_path";
		interconnects = <&system_noc MASTER_CRYPTO_CORE0 &bimc SLAVE_EBI_CH0>;
		qcom,smmu-s1-enable;
		iommus = <&apps_smmu 0x0086 0x0011>,
			 <&apps_smmu 0x0096 0x0011>;
		qcom,iommu-dma = "atomic";

		qcom_cedev_ns_cb {
			compatible = "qcom,qcedev,context-bank";
			label = "ns_context";
			iommus = <&apps_smmu 0x92 0>,
				<&apps_smmu 0x98 0x1>,
				<&apps_smmu 0x9F 0>;
		};

		qcom_cedev_s_cb {
			compatible = "qcom,qcedev,context-bank";
			label = "secure_context";
			iommus = <&apps_smmu 0x93 0>,
				<&apps_smmu 0x9C 0x1>,
				<&apps_smmu 0x9E 0>;
			qcom,iommu-vmid = <0x9>; /* VMID_CP_BITSTREAM */
			qcom,secure-context-bank;
		};
	};

	qcom_crypto: qcrypto@1b20000 {
		compatible = "qcom,qcrypto";
		reg = <0x1b20000 0x20000>,
			<0x1b04000 0x24000>;
		reg-names = "crypto-base","crypto-bam-base";
		interrupts = <GIC_SPI 247 IRQ_TYPE_LEVEL_HIGH>;
		qcom,bam-pipe-pair = <2>;
		qcom,ce-hw-instance = <0>;
		qcom,ce-device = <0>;
		qcom,bam-ee = <0>;
		qcom,ce-hw-shared;
		qcom,clk-mgmt-sus-res;
		qcom,msm-bus,name = "qcrypto-noc";
		qcom,msm-bus,num-cases = <2>;
		qcom,msm-bus,num-paths = <1>;
		clock-names =
			"core_clk_src", "core_clk",
			"iface_clk", "bus_clk";
		clocks =
			<&rpmcc RPM_SMD_CE1_CLK>,
			<&rpmcc RPM_SMD_CE1_CLK>,
			<&rpmcc RPM_SMD_CE1_CLK>,
			<&rpmcc RPM_SMD_CE1_CLK>;
		qcom,use-sw-aes-cbc-ecb-ctr-algo;
		qcom,use-sw-aes-xts-algo;
		qcom,use-sw-aes-ccm-algo;
		qcom,use-sw-ahash-algo;
		qcom,use-sw-aead-algo;
		qcom,use-sw-hmac-algo;
		interconnect-names = "data_path";
		interconnects = <&system_noc MASTER_CRYPTO_CORE0 &bimc SLAVE_EBI_CH0>;
		qcom,smmu-s1-enable;
		iommus = <&apps_smmu 0x0084 0x0011>,
			<&apps_smmu 0x0094 0x0011>;
		qcom,iommu-dma = "atomic";
	};

	qcom,mpm2-sleep-counter@4403000 {
		compatible = "qcom,mpm2-sleep-counter";
		reg = <0x4403000 0x1000>;
		clock-frequency = <32768>;
	};

	qcom,memshare {
		compatible = "qcom,memshare";

		qcom,client_1 {
			compatible = "qcom,memshare-peripheral";
			qcom,peripheral-size = <0x0>;
			qcom,client-id = <0>;
			qcom,allocate-boot-time;
			label = "modem";
		};

		qcom,client_2 {
			compatible = "qcom,memshare-peripheral";
			qcom,peripheral-size = <0x0>;
			qcom,client-id = <2>;
			label = "modem";
		};

		mem_client_3_size: qcom,client_3 {
			compatible = "qcom,memshare-peripheral";
			qcom,peripheral-size = <0x500000>;
			qcom,client-id = <1>;
			qcom,allocate-on-request;
			label = "modem";
		};
	};

	qcom,msm-rtb {
		compatible = "qcom,msm-rtb";
		qcom,rtb-size = <0x100000>;
	};

	cpu_pmu: cpu-pmu {
		compatible = "arm,armv8-pmuv3";
		qcom,irq-is-percpu;
		interrupts = <1 6 4>;
	};

	qcom,chd_silver {
		compatible = "qcom,core-hang-detect";
		label = "silver";
		qcom,threshold-arr = <0x0f1880b0 0x0f1980b0
				      0x0f1a80b0 0x0f1b80b0>;
		qcom,config-arr = <0x0f1880b8 0x0f1980b8
				   0x0f1a80b8 0x0f1b80b8>;
	};

	eud: qcom,msm-eud@1610000 {
		compatible = "qcom,msm-eud";
		interrupt-names = "eud_irq";
		interrupts = <GIC_SPI 189 IRQ_TYPE_LEVEL_HIGH>;
		reg = <0x1610000 0x2000>,
		      <0x1612000 0x1000>,
		      <0x3E5018 0x4>;
		reg-names = "eud_base", "eud_mode_mgr2",
				"eud_tcsr_check_reg";
		qcom,secure-eud-en;
		qcom,eud-tcsr-check-enable;
		qcom,eud-clock-vote-req;
		clocks = <&gcc GCC_AHB2PHY_USB_CLK>;
		clock-names = "eud_ahb2phy_clk";
		status = "ok";
	};

	wdog: qcom,wdt@f017000 {
		compatible = "qcom,msm-watchdog";
		reg = <0xf017000 0x1000>;
		reg-names = "wdt-base";
		interrupts = <GIC_SPI 3 IRQ_TYPE_EDGE_RISING>,
			     <GIC_SPI 4 IRQ_TYPE_LEVEL_HIGH>;
		qcom,bark-time = <11000>;
		qcom,pet-time = <9360>;
		qcom,ipi-ping;
		qcom,wakeup-enable;
	};

	qfprom: qfprom@1b40000 {
		compatible = "qcom,qfprom";
		reg = <0x1b40000 0x7000>;
		#address-cells = <1>;
		#size-cells = <1>;
		read-only;
		ranges;

		feat_conf5: feat_conf5@6018 {
			reg = <0x6018 0x4>;
		};

		gpu_speed_bin: gpu_speed_bin@6006 {
			reg = <0x6006 0x2>;
			bits = <5 8>;
		};

		adsp_variant: adsp_variant@6011 {
			reg = <0x6011 0x1>;
			bits = <3 1>;
		};
	};

	qcom,sps {
		compatible = "qcom,msm-sps-4k";
		qcom,pipe-attr-ee;
	};

	adsp_pas:remoteproc-adsp@ab00000 {
		compatible = "qcom,scuba-adsp-pas";
		reg = <0xab00000 0x00100>;

		clocks = <&rpmcc RPM_SMD_XO_CLK_SRC>;
		clock-names = "xo";

		cx-supply = <&VDD_LPI_CX_LEVEL>;
		cx-uV-uA = <RPMH_REGULATOR_LEVEL_TURBO 0>;
		mx-supply = <&VDD_LPI_MX_LEVEL>;
		mx-uV-uA = <RPMH_REGULATOR_LEVEL_TURBO 0>;
		reg-names = "cx", "mx";

		memory-region = <&pil_adsp_mem>;

		/* Inputs from lpass */
		interrupts-extended = <&intc 0 282 IRQ_TYPE_EDGE_RISING>,
				      <&adsp_smp2p_in 0 0>,
				      <&adsp_smp2p_in 2 0>,
				      <&adsp_smp2p_in 1 0>,
				      <&adsp_smp2p_in 3 0>;

		interrupt-names = "wdog",
				  "fatal",
				  "handover",
				  "ready",
				  "stop-ack";

		/* Outputs to lpass */
		qcom,smem-states = <&adsp_smp2p_out 0>;
		qcom,smem-state-names = "stop";

		glink_edge: glink-edge {
			qcom,remote-pid = <2>;
			transport = "smem";
			mboxes = <&apcs_glb 8>;
			mbox-names = "adsp_smem";
			interrupts = <GIC_SPI 277 IRQ_TYPE_EDGE_RISING>;

			label = "adsp";
			qcom,glink-label = "lpass";

			qcom,adsp_qrtr {
				qcom,glink-channels = "IPCRTR";
				qcom,intents = <0x800  5
						0x2000 3
						0x4400 2>;
				qcom,no-wake-svc = <0x190>;
			};

			qcom,msm_fastrpc_rpmsg {
				compatible = "qcom,msm-fastrpc-rpmsg";
				qcom,glink-channels = "fastrpcglink-apps-dsp";
				qcom,intents = <0x64 64>;
			};

			qcom,apr_tal_rpmsg {
				qcom,glink-channels = "apr_audio_svc";
				qcom,intents = <0x200 20>;
			};
		};
	};

	cx_ipeak_lm: cx_ipeak@3ed000 {
		compatible = "qcom,cx-ipeak-v2";
		reg = <0x3ed000 0xe008>;
		interrupts = <0 415 IRQ_TYPE_EDGE_RISING>,
			     <0 416 IRQ_TYPE_EDGE_RISING>;
		interrupt-names = "cx_ipeak_danger", "cx_ipeak_safe";
		victims_table = <4 0 844800000>;
	};

	modem_pas: remoteproc-mss@6080000 {
		compatible = "qcom,scuba-modem-pas";
		reg = <0x6080000 0x100>;

		clocks = <&rpmcc RPM_SMD_XO_CLK_SRC>;
		clock-names = "xo";

		cx-supply = <&VDD_CX_LEVEL>;
		cx-uV-uA = <RPMH_REGULATOR_LEVEL_TURBO 100000>;
		reg-names = "cx";

		memory-region = <&pil_modem_mem>;

		/* Inputs from mss */
		interrupts-extended = <&intc 0 307 1>,
				<&modem_smp2p_in 0 0>,
				<&modem_smp2p_in 2 0>,
				<&modem_smp2p_in 1 0>,
				<&modem_smp2p_in 3 0>,
				<&modem_smp2p_in 7 0>;

		interrupt-names = "wdog",
				"fatal",
				"handover",
				"ready",
				"stop-ack",
				"shutdown-ack";

		/* Outputs to mss */
		qcom,smem-states = <&modem_smp2p_out 0>;
		qcom,smem-state-names = "stop";

		glink-edge {
			qcom,remote-pid = <1>;
			transport = "smem";
			mboxes = <&apcs_glb 12>;
			mbox-names = "mpss_smem";
			interrupts = <GIC_SPI 68 IRQ_TYPE_EDGE_RISING>;

			label = "modem";
			qcom,glink-label = "mpss";

			qcom,modem_qrtr {
				qcom,glink-channels = "IPCRTR";
				qcom,intents = <0x800  5
						0x2000 3
						0x4400 2>;
			};

			qcom,msm_fastrpc_rpmsg {
				compatible = "qcom,msm-fastrpc-rpmsg";
				qcom,glink-channels = "fastrpcglink-apps-dsp";
				qcom,intents = <0x64 64>;
			};

			qcom,modem_ds {
				qcom,glink-channels = "DS";
				qcom,intents = <0x4000 2>;
			};
		};
	};

	thermal_zones: thermal-zones { };

	clk_virt: interconnect@0 {
		compatible = "qcom,scuba-clk_virt";
		qcom,keepalive;
		#interconnect-cells = <1>;
		clock-names = "bus", "bus_a";
		clocks = <&rpmcc RPM_SMD_QUP_CLK>,
			<&rpmcc RPM_SMD_QUP_A_CLK>;
	};

	system_noc: interconnect0@1880000 {
		reg = <0x1880000 0x5e080>;
		compatible = "qcom,scuba-sys_noc";
		qcom,keepalive;
		#interconnect-cells = <1>;
		clock-names = "bus", "bus_a";
		clocks = <&rpmcc RPM_SMD_SNOC_CLK>,
			<&rpmcc RPM_SMD_SNOC_A_CLK>;
	};

	mmnrt_virt: interconnect1@1880000 {
		reg = <0x1880000 0x5e080>;
		compatible = "qcom,scuba-mmnrt_virt";
		qcom,util-factor = <142>;
		qcom,keepalive;
		#interconnect-cells = <1>;
		clock-names = "bus", "bus_a";
		clocks = <&rpmcc RPM_SMD_MMNRT_CLK>,
			<&rpmcc RPM_SMD_MMNRT_A_CLK>;
	};

	mmrt_virt: interconnect2@1880000 {
		reg = <0x1880000 0x5e080>;
		compatible = "qcom,scuba-mmrt_virt";
		qcom,util-factor = <139>;
		qcom,keepalive;
		#interconnect-cells = <1>;
		clock-names = "bus", "bus_a";
		clocks = <&rpmcc RPM_SMD_MMRT_CLK>,
			<&rpmcc RPM_SMD_MMRT_A_CLK>;
	};

	config_noc: interconnect@1900000 {
		reg = <0x01900000 0x9200>;
		compatible = "qcom,scuba-config_noc";
		qcom,keepalive;
		#interconnect-cells = <1>;
		clock-names = "bus", "bus_a";
		clocks = <&rpmcc RPM_SMD_CNOC_CLK>,
			<&rpmcc RPM_SMD_CNOC_A_CLK>;
	};

	bimc: interconnect@4480000 {
		reg = <0x4480000 0x80000>;
		compatible = "qcom,scuba-bimc";
		qcom,util-factor = <153>;
		qcom,keepalive;
		#interconnect-cells = <1>;
		clock-names = "bus", "bus_a";
		clocks = <&rpmcc RPM_SMD_BIMC_CLK>,
			<&rpmcc RPM_SMD_BIMC_A_CLK>;
	};

	rpm_bus: qcom,rpm-smd {
		compatible = "qcom,rpm-smd";
		rpm-channel-name = "rpm_requests";
		interrupts = <GIC_SPI 194 IRQ_TYPE_EDGE_RISING>;
		rpm-channel-type = <15>; /* SMD_APPS_RPM */
		power-domains = <&CLUSTER_PD>;
	};

	cluster-device {
		compatible = "qcom,lpm-cluster-dev";
		power-domains = <&CLUSTER_PD>;
	};

	rpm-stats@4690000 {
		compatible = "qcom,rpm-sleep-stats";
		reg = <0x04690000 0x400>;
	};

	qcom,rpm-master-stats@45f0150 {
		compatible = "qcom,rpm-master-stats";
		reg = <0x45f0150 0x5000>;
		qcom,masters = "APSS", "MPSS", "ADSP", "CDSP", "TZ";
		qcom,master-stats-version = <2>;
		qcom,master-offset = <4096>;
	};

	mem_dump {
		compatible = "qcom,mem-dump";
		memory-region = <&dump_mem>;

		c0_context {
			qcom,dump-size = <0x800>;
			qcom,dump-id = <0x0>;
		};

		c1_context {
			qcom,dump-size = <0x800>;
			qcom,dump-id = <0x1>;
		};

		c2_context {
			qcom,dump-size = <0x800>;
			qcom,dump-id = <0x2>;
		};

		c3_context {
			qcom,dump-size = <0x800>;
			qcom,dump-id = <0x3>;
		};

		l1_icache0 {
			qcom,dump-size = <0x9040>;
			qcom,dump-id = <0x60>;
		};

		l1_icache1 {
			qcom,dump-size = <0x9040>;
			qcom,dump-id = <0x61>;
		};

		l1_icache2 {
			qcom,dump-size = <0x9040>;
			qcom,dump-id = <0x62>;
		};

		l1_icache3 {
			qcom,dump-size = <0x9040>;
			qcom,dump-id = <0x63>;
		};

		l1_dcache0 {
			qcom,dump-size = <0x9040>;
			qcom,dump-id = <0x80>;
		};

		l1_dcache1 {
			qcom,dump-size = <0x9040>;
			qcom,dump-id = <0x81>;
		};

		l1_dcache2 {
			qcom,dump-size = <0x9040>;
			qcom,dump-id = <0x82>;
		};

		l1_dcache3 {
			qcom,dump-size = <0x9040>;
			qcom,dump-id = <0x83>;
		};

		l2_tlb0 {
			qcom,dump-size = <0x2000>;
			qcom,dump-id = <0x120>;
		};

		l2_tlb1 {
			qcom,dump-size = <0x2000>;
			qcom,dump-id = <0x121>;
		};

		l2_tlb2 {
			qcom,dump-size = <0x2000>;
			qcom,dump-id = <0x122>;
		};

		l2_tlb3 {
			qcom,dump-size = <0x2000>;
			qcom,dump-id = <0x123>;
		};

		rpm_sw {
			qcom,dump-size = <0x28000>;
			qcom,dump-id = <0xea>;
		};

		pmic {
			qcom,dump-size = <0x40000>;
			qcom,dump-id = <0xe4>;
		};

		fcm {
			qcom,dump-size = <0x8400>;
			qcom,dump-id = <0xee>;
		};

		tmc_etf {
			qcom,dump-size = <0x8000>;
			qcom,dump-id = <0xf0>;
		};

		etr_reg {
			qcom,dump-size = <0x1000>;
			qcom,dump-id = <0x100>;
		};

		etf_reg {
			qcom,dump-size = <0x1000>;
			qcom,dump-id = <0x101>;
		};

		misc_data {
			qcom,dump-size = <0x1000>;
			qcom,dump-id = <0xe8>;
		};
	};

	sdhc1_opp_table: sdhc1-opp-table {
		compatible = "operating-points-v2";

		opp-100000000 {
			opp-hz = /bits/ 64 <100000000>;
			opp-peak-kBps = <250000 133320>;
			opp-avg-kBps = <104000 0>;
		};

		opp-384000000 {
			opp-hz = /bits/ 64 <384000000>;
			opp-peak-kBps = <800000 300000>;
			opp-avg-kBps = <400000 0>;
		};
	};

	sdhc_1: sdhci@4744000 {
		status = "disabled";

		compatible = "qcom,sdhci-msm-v5";
		reg = <0x4744000 0x1000>, <0x4745000 0x1000>, <0x4748000 0x8000>;
		reg-names = "hc", "cqhci", "cqhci_ice";

		interrupts = <GIC_SPI 348 IRQ_TYPE_LEVEL_HIGH>,
				<GIC_SPI 352 IRQ_TYPE_LEVEL_HIGH>;
		interrupt-names = "hc_irq", "pwr_irq";

		bus-width = <8>;
		non-removable;
		supports-cqe;

		cap-mmc-hw-reset;

		no-sd;
		no-sdio;
		qcom,restore-after-cx-collapse;

		mmc-ddr-1_8v;
		mmc-hs200-1_8v;

		mmc-hs400-1_8v;
		mmc-hs400-enhanced-strobe;

		qcom,devfreq,freq-table = <50000000 200000000>;

		qcom,scaling-lower-bus-speed-mode = "DDR52";

		clocks = <&gcc GCC_SDCC1_AHB_CLK>,
			<&gcc GCC_SDCC1_APPS_CLK>,
			<&gcc GCC_SDCC1_ICE_CORE_CLK>;
		clock-names = "iface", "core", "ice_core";

		qcom,ice-clk-rates = <300000000 100000000>;

		interconnects = <&system_noc MASTER_SDCC_1 &bimc SLAVE_EBI_CH0>,
			<&bimc MASTER_AMPSS_M0 &config_noc SLAVE_SDCC_1>;
		interconnect-names = "sdhc-ddr","cpu-sdhc";
		operating-points-v2 = <&sdhc1_opp_table>;

		/* Add support for gcc hw reset */
		resets = <&gcc GCC_SDCC1_BCR>;
		reset-names = "core_reset";

		/* DLL HSR settings. Refer go/hsr - <Target> DLL settings */
		qcom,dll-hsr-list = <0x000f642c 0x0 0x0 0x00010800 0x80040868>;

		iommus = <&apps_smmu 0xC0 0x0>;
		qcom,iommu-dma = "fastmap";

		qos0 {
			mask = <0xf0>;
			vote = <43>;
		};

	};

	sdhc2_opp_table: sdhc1-opp-table {
		compatible = "operating-points-v2";

		opp-100000000 {
			opp-hz = /bits/ 64 <100000000>;
			opp-peak-kBps = <250000 133320>;
			opp-avg-kBps = <50000 0>;
		};

		opp-202000000 {
			opp-hz = /bits/ 64 <202000000>;
			opp-peak-kBps = <800000 300000>;
			opp-avg-kBps = <104000 0>;
		};
	};

	sdhc_2: sdhci@4784000 {
		status = "disabled";

		compatible = "qcom,sdhci-msm-v5";
		reg = <0x4784000 0x1000>;
		reg-names = "hc";

		interrupts = <GIC_SPI 350 IRQ_TYPE_LEVEL_HIGH>,
				<GIC_SPI 353 IRQ_TYPE_LEVEL_HIGH>;
		interrupt-names = "hc_irq", "pwr_irq";

		bus-width = <4>;
		no-sdio;

		no-mmc;
		qcom,restore-after-cx-collapse;

		qcom,clk-rates = <400000 20000000 25000000
				50000000 100000000 202000000>;

		qcom,devfreq,freq-table = <50000000 202000000>;

		clocks = <&gcc GCC_SDCC2_AHB_CLK>,
			<&gcc GCC_SDCC2_APPS_CLK>;
		clock-names = "iface", "core";

		interconnects = <&system_noc MASTER_SDCC_2 &bimc SLAVE_EBI_CH0>,
			<&bimc MASTER_AMPSS_M0 &config_noc SLAVE_SDCC_2>;
		interconnect-names = "sdhc-ddr","cpu-sdhc";
		operating-points-v2 = <&sdhc2_opp_table>;

		/* DLL HSR settings. Refer go/hsr - <Target> DLL settings */
		qcom,dll-hsr-list = <0x0007642c 0x0 0x0 0x00010800 0x80040868>;

		iommus = <&apps_smmu 0xA0 0x0>;
		qcom,iommu-dma = "fastmap";

		qos0 {
			mask = <0xf0>;
			vote = <43>;
		};
	};

	qcom,secure-buffer {
		compatible = "qcom,secure-buffer";
	};

	logbuf: qcom,logbuf-vendor-hooks {
		compatible = "qcom,logbuf-vendor-hooks";
	};

	qcom,mem-buf {
		compatible = "qcom,mem-buf";
		qcom,vmid = <3>;
		qcom,mem-buf-capabilities = "supplier";
	};

	qcom,mem-buf-msgq {
		compatible = "qcom,mem-buf-msgq";
	};

	clocks {
		xo_board: xo-board {
			compatible = "fixed-clock";
			clock-frequency = <38400000>;
			clock-output-names = "xo_board";
			#clock-cells = <0>;
		};

		sleep_clk: sleep-clk {
			compatible = "fixed-clock";
			clock-frequency = <32764>;
			clock-output-names = "chip_sleep_clk";
			#clock-cells = <0>;
		};
	};

	rpmcc: qcom,rpmcc {
		compatible = "qcom,rpmcc-scuba";
		#clock-cells = <1>;
	};

	qcom,rmtfs_sharedmem@0 {
		compatible = "qcom,sharedmem-uio";
		reg = <0x0 0x200000>;
		reg-names = "rmtfs";
		qcom,client-id = <0x00000001>;
		qcom,guard-memory;
		qcom,vm-nav-path;
	};

	gcc: clock-controller@1400000 {
		compatible = "qcom,scuba-gcc", "syscon";
		reg = <0x1400000 0x1f0000>;
		reg-names = "cc_base";
		vdd_cx-supply = <&VDD_CX_LEVEL>;
		vdd_cx_ao-supply = <&VDD_CX_LEVEL_AO>;
		vdd_mx-supply = <&VDD_MX_LEVEL>;
		clocks = <&rpmcc RPM_SMD_XO_CLK_SRC>,
			 <&rpmcc RPM_SMD_XO_A_CLK_SRC>,
			 <&sleep_clk>;
		clock-names = "bi_tcxo", "bi_tcxo_ao", "sleep_clk";
		#clock-cells = <1>;
		#reset-cells = <1>;
	};

	dispcc: clock-controller@5f00000 {
		compatible = "qcom,scuba-dispcc", "syscon";
		reg = <0x5f00000 0x20000>;
		reg-names = "cc_base";
		vdd_cx-supply = <&VDD_CX_LEVEL>;
		clocks = <&rpmcc RPM_SMD_XO_CLK_SRC>,
			 <&rpmcc RPM_SMD_XO_A_CLK_SRC>,
			 <&gcc GCC_DISP_GPLL0_DIV_CLK_SRC>,
			 <&gcc GCC_DISP_AHB_CLK>,
			 <&sleep_clk>;
		clock-names = "bi_tcxo", "bi_tcxo_ao",
				"gcc_disp_gpll0_div_clk_src",
				"iface", "sleep_clk";
		#clock-cells = <1>;
		#reset-cells = <1>;
	};

	gpucc: clock-controller@5990000 {
		compatible = "qcom,scuba-gpucc", "syscon";
		reg = <0x5990000 0x9000>;
		reg-names = "cc_base";
		vdd_cx-supply = <&VDD_CX_LEVEL>;
		clocks = <&rpmcc RPM_SMD_XO_CLK_SRC>, <&gcc GPLL0>;
		clock-names = "bi_tcxo", "gpll0_out_main";
		#clock-cells = <1>;
		#reset-cells = <1>;
	};

	mccc_debug: syscon@447d200 {
		compatible = "syscon";
		reg = <0x447d200 0x100>;
	};

	cpucc_debug: syscon@f11101c {
		compatible = "syscon";
		reg = <0xf11101c 0x4>;
	};

	debugcc: clock-controller@0 {
		compatible = "qcom,scuba-debugcc";
		qcom,gcc = <&gcc>;
		qcom,dispcc = <&dispcc>;
		qcom,gpucc = <&gpucc>;
		qcom,mccc = <&mccc_debug>;
		qcom,cpucc = <&cpucc_debug>;
		clocks = <&rpmcc RPM_SMD_XO_CLK_SRC>,
			 <&gcc 0>,
			 <&dispcc 0>,
			 <&gpucc 0>;
		clock-names = "xo_clk_src",
			      "gcc",
			      "dispcc",
			      "gpucc";
		#clock-cells = <1>;
	};

	cpufreq_hw: qcom,cpufreq-hw {
		compatible = "qcom,cpufreq-hw";
		reg = <0xf521000 0x1400>;
		reg-names = "freq-domain0";
		clocks = <&rpmcc RPM_SMD_XO_CLK_SRC>, <&gcc GPLL0>;
		clock-names = "xo", "alternate";
		qcom,no-accumulative-counter;
		qcom,max-lut-entries = <12>;
		#freq-domain-cells = <2>;
	};

	qcom,cpufreq-hw-debug@f521000 {
		compatible = "qcom,cpufreq-hw-debug";
		reg = <0xf521000 0x1400>;
		reg-names = "domain-top";
		qcom,freq-hw-domain = <&cpufreq_hw 0>;
	};

	qcom_pmu: qcom,pmu {
		compatible = "qcom,pmu";
		qcom,pmu-events-tbl =
			< 0x0008 0xFF 0xFF 0xFF >,
			< 0x0011 0xFF 0xFF 0xFF >,
			< 0x0017 0xFF 0xFF 0xFF >;
	};

	ddr_freq_table: ddr-freq-table {
		ddr3 {
			qcom,ddr-type = <5>;
			qcom,freq-tbl =
				<  200000 >,
				<  451000 >,
				<  547000 >,
				<  768000 >,
				<  931000 >;
		};

		ddr4 {
			qcom,ddr-type = <7>;
			qcom,freq-tbl =
				<  300000 >,
				<  451000 >,
				<  547000 >,
				<  768000 >,
				< 1017000 >,
				< 1353000 >,
				< 1555000 >,
				< 1804000 >;
		};
	};

	qcom_dcvs: qcom,dcvs {
		compatible = "qcom,dcvs";
		#address-cells = <1>;
		#size-cells = <1>;
		ranges;

		qcom_ddr_dcvs_hw: ddr {
			compatible = "qcom,dcvs-hw";
			qcom,dcvs-hw-type = <0>;
			qcom,bus-width = <8>;
			qcom,freq-tbl = <&ddr_freq_table>;

			ddr_dcvs_sp: sp {
				compatible = "qcom,dcvs-path";
				qcom,dcvs-path-type = <0>;
				interconnects = <&bimc MASTER_AMPSS_M0 &bimc SLAVE_EBI_CH0>;
			};
		};
	};

	bwmon_ddr: qcom,bwmon-ddr@01b8e200 {
		compatible = "qcom,bwmon4";
		reg = <0x01b8e300 0x100>, <0x01b8e200 0x100>;
		reg-names = "base", "global_base";
		interrupts = <GIC_SPI 421 IRQ_TYPE_LEVEL_HIGH>;
		qcom,mport = <0>;
		qcom,hw-timer-hz = <19200000>;
		qcom,target-dev = <&qcom_ddr_dcvs_hw>;
		qcom,count-unit = <0x10000>;
	};

	qcom_memlat: qcom,memlat {
		compatible = "qcom,memlat";
		ddr {
			compatible = "qcom,memlat-grp";
			qcom,target-dev = <&qcom_ddr_dcvs_hw>;
			qcom,sampling-path = <&ddr_dcvs_sp>;
			qcom,miss-ev = <0x17>;

			gold {
				compatible = "qcom,memlat-mon";
				qcom,cpulist = <&CPU0 &CPU1 &CPU2 &CPU3>;
				qcom,sampling-enabled;
				ddr3-tbl {
					qcom,ddr-type = <5>;
					qcom,cpufreq-memfreq-tbl =
							<  614400 200000 >,
							< 1017600 451000 >,
							< 1420000 547000 >,
							< 1612800 768000 >,
							< 2000000 931000 >;
				};

				ddr4-tbl {
					qcom,ddr-type = <7>;
					qcom,cpufreq-memfreq-tbl =
							<  614400  451000 >,
							< 1017600  768000 >,
							< 1420000 1017000 >,
							< 1612800 1555000 >,
							< 2000000 1804000 >;
				};
			};

			gold-compute {
				compatible = "qcom,memlat-mon";
				qcom,cpulist = <&CPU0 &CPU1 &CPU2 &CPU3>;
				qcom,sampling-enabled;
				qcom,compute-mon;
				ddr3-tbl {
					qcom,ddr-type = <5>;
					qcom,cpufreq-memfreq-tbl =
						<  864000 200000 >,
						< 1017600 300000 >,
						< 1420000 451000 >,
						< 1804800 547000 >,
						< 2000000 931000 >;
				};

				ddr4-tbl {
					qcom,ddr-type = <7>;
					qcom,cpufreq-memfreq-tbl =
						<  864000  300000 >,
						< 1017600  547000 >,
						< 1420000  768000 >,
						< 1804800 1017000 >,
						< 2000000 1804000 >;
				};
			};
		};
	};

	dload_mode {
		compatible = "qcom,dload-mode";
	};

	mini_dump_mode {
		compatible = "qcom,minidump";
		status = "ok";
	};

	va_mini_dump {
		compatible = "qcom,va-minidump";
		memory-region = <&va_md_mem>;
		status = "ok";
	};

	tcsr_mutex_block: syscon@00340000 {
		compatible = "syscon";
		reg = <0x340000 0x20000>;
	};

	tcsr_mutex: hwlock {
		compatible = "qcom,tcsr-mutex";
		syscon = <&tcsr_mutex_block 0 0x1000>;
		#hwlock-cells = <1>;
	};

	smem: qcom,smem {
		compatible = "qcom,smem";
		memory-region = <&smem_region>;
		hwlocks = <&tcsr_mutex 3>;
	};

	rpm_msg_ram: memory@045f0000 {
			compatible = "qcom,rpm-msg-ram";
			reg = <0x45f0000 0x7000>;
	};

	apcs_glb: mailbox@0f111000 {
		compatible = "qcom,scuba-apcs-hmss-global";
		reg = <0xF111000 0x1000>;

		#mbox-cells = <1>;
	};

	qcom,msm-adsprpc-mem {
		compatible = "qcom,msm-adsprpc-mem-region";
		memory-region = <&adsp_mem>;
		restrict-access;
	};

	qcom,msm_fastrpc {
		compatible = "qcom,msm-fastrpc-compute";
		qcom,rpc-latency-us = <611>;
		qcom,adsp-remoteheap-vmid = <22 37>;
		qcom,fastrpc-adsp-audio-pdr;
		qcom,fastrpc-adsp-sensors-pdr;

		qcom,msm_fastrpc_compute_cb1 {
			compatible = "qcom,msm-fastrpc-compute-cb";
			label = "adsprpc-smd";
			iommus = <&apps_smmu 0x01C3 0x0>;
			qcom,iommu-dma-addr-pool = <0x80000000 0x78000000>;
			qcom,iommu-faults = "stall-disable", "HUPCF";
		};

		qcom,msm_fastrpc_compute_cb2 {
			compatible = "qcom,msm-fastrpc-compute-cb";
			label = "adsprpc-smd";
			iommus = <&apps_smmu 0x01C4 0x0>;
			qcom,iommu-dma-addr-pool = <0x80000000 0x78000000>;
			qcom,iommu-faults = "stall-disable", "HUPCF";
		};

		qcom,msm_fastrpc_compute_cb3 {
			compatible = "qcom,msm-fastrpc-compute-cb";
			label = "adsprpc-smd";
			iommus = <&apps_smmu 0x01C5 0x0>;
			qcom,iommu-dma-addr-pool = <0x80000000 0x78000000>;
			qcom,iommu-faults = "stall-disable", "HUPCF";
		};

		qcom,msm_fastrpc_compute_cb4 {
			compatible = "qcom,msm-fastrpc-compute-cb";
			label = "adsprpc-smd";
			iommus = <&apps_smmu 0x01C6 0x0>;
			qcom,iommu-dma-addr-pool = <0x80000000 0x78000000>;
			qcom,iommu-faults = "stall-disable", "HUPCF";
		};

		qcom,msm_fastrpc_compute_cb5 {
			compatible = "qcom,msm-fastrpc-compute-cb";
			label = "adsprpc-smd";
			iommus = <&apps_smmu 0x01C7 0x0>;
			qcom,iommu-dma-addr-pool = <0x80000000 0x78000000>;
			qcom,iommu-faults = "stall-disable", "HUPCF";
		};

	};

	rpm-glink {
		compatible = "qcom,glink-rpm";
		interrupts = <GIC_SPI 194 IRQ_TYPE_EDGE_RISING>;
		qcom,rpm-msg-ram = <&rpm_msg_ram>;
		mboxes = <&apcs_glb 0>;
	};

	qcom,glinkpkt {
		compatible = "qcom,glinkpkt";

		qcom,glinkpkt-at-mdm0 {
			qcom,glinkpkt-edge = "mpss";
			qcom,glinkpkt-ch-name = "DS";
			qcom,glinkpkt-dev-name = "at_mdm0";
		};

		qcom,glinkpkt-apr-apps2 {
			qcom,glinkpkt-edge = "adsp";
			qcom,glinkpkt-ch-name = "apr_apps2";
			qcom,glinkpkt-dev-name = "apr_apps2";
		};

		qcom,glinkpkt-data40-cntl {
			qcom,glinkpkt-edge = "mpss";
			qcom,glinkpkt-ch-name = "DATA40_CNTL";
			qcom,glinkpkt-dev-name = "smdcntl8";
		};

		qcom,glinkpkt-data1 {
			qcom,glinkpkt-edge = "mpss";
			qcom,glinkpkt-ch-name = "DATA1";
			qcom,glinkpkt-dev-name = "smd7";
		};

		qcom,glinkpkt-data4 {
			qcom,glinkpkt-edge = "mpss";
			qcom,glinkpkt-ch-name = "DATA4";
			qcom,glinkpkt-dev-name = "smd8";
		};

		qcom,glinkpkt-data11 {
			qcom,glinkpkt-edge = "mpss";
			qcom,glinkpkt-ch-name = "DATA11";
			qcom,glinkpkt-dev-name = "smd11";
		};
	};

	qcom,glink {
		compatible = "qcom,glink";
	};

	tcsr: syscon@0x003C0000 {
		compatible = "syscon";
		reg = <0x003C0000 0x40000>;
	};

	qcom,smp2p_sleepstate {
		compatible = "qcom,smp2p-sleepstate";
		qcom,smem-states = <&sleepstate_smp2p_out 0>;
		interrupt-parent = <&sleepstate_smp2p_in>;
		interrupts = <0 0>;
		interrupt-names = "smp2p-sleepstate-in";
	};

	qcom,smp2p-modem {
		compatible = "qcom,smp2p";
		qcom,smem = <435>, <428>;
		interrupts = <GIC_SPI 70 IRQ_TYPE_EDGE_RISING>;
		mboxes = <&apcs_glb 14>;
		qcom,local-pid = <0>;
		qcom,remote-pid = <1>;

		modem_smp2p_out: master-kernel {
			qcom,entry-name = "master-kernel";
			#qcom,smem-state-cells = <1>;
		};

		modem_smp2p_in: slave-kernel {
			qcom,entry-name = "slave-kernel";
			interrupt-controller;
			#interrupt-cells = <2>;
		};

		smp2p_ipa_1_out: qcom,smp2p-ipa-1-out {
			qcom,entry-name = "ipa";
			#qcom,smem-state-cells = <1>;
		};

		/* ipa - inbound entry from mss */
		smp2p_ipa_1_in: qcom,smp2p-ipa-1-in {
			qcom,entry-name = "ipa";
			interrupt-controller;
			#interrupt-cells = <2>;
		};

		smp2p_wlan_1_in: qcom,smp2p-wlan-1-in {
			qcom,entry-name = "wlan";
			interrupt-controller;
			#interrupt-cells = <2>;
		};

	};

	qcom,smp2p-adsp {
		compatible = "qcom,smp2p";
		qcom,smem = <443>, <429>;
		interrupts = <GIC_SPI 279 IRQ_TYPE_EDGE_RISING>;
		mboxes = <&apcs_glb 10>;
		qcom,local-pid = <0>;
		qcom,remote-pid = <2>;

		adsp_smp2p_out: master-kernel {
			qcom,entry-name = "master-kernel";
			#qcom,smem-state-cells = <1>;
		};

		adsp_smp2p_in: slave-kernel {
			qcom,entry-name = "slave-kernel";
			interrupt-controller;
			#interrupt-cells = <2>;
		};

		smp2p_rdbg2_out: qcom,smp2p-rdbg2-out {
			qcom,entry-name = "rdbg";
			#qcom,smem-state-cells = <1>;
		};

		smp2p_rdbg2_in: qcom,smp2p-rdbg2-in {
			qcom,entry-name = "rdbg";
			interrupt-controller;
			#interrupt-cells = <2>;
		};

		sleepstate_smp2p_out: sleepstate-out {
			qcom,entry-name = "sleepstate";
			#qcom,smem-state-cells = <1>;
		};

		sleepstate_smp2p_in: qcom,sleepstate-in {
			qcom,entry-name = "sleepstate_see";
			interrupt-controller;
			#interrupt-cells = <2>;
		};
	};

	spmi_bus: qcom,spmi@1c40000 {
		compatible = "qcom,spmi-pmic-arb";
		reg = <0x1c40000 0x1100>,
			<0x1e00000 0x2000000>,
			<0x3e00000 0x100000>,
			<0x3f00000 0xa0000>,
			<0x1c0a000 0x26000>;
		reg-names = "core", "chnls", "obsrvr", "intr", "cnfg";
		interrupt-names = "periph_irq";
		interrupts-extended = <&mpm 86 IRQ_TYPE_LEVEL_HIGH>;
		qcom,ee = <0>;
		qcom,channel = <0>;
		#address-cells = <1>;
		#size-cells = <1>;
		interrupt-controller;
		#interrupt-cells = <4>;
		cell-index = <0>;
	};

	bluetooth: bt_wcn3990 {
		compatible = "qca,wcn3990";
		qca,bt-sw-ctrl-gpio = <&tlmm 87 0>; /* SW_CTRL */
		qca,bt-vdd-io-supply =   <&L15A>; /* IO */
		qca,bt-vdd-core-supply = <&L10A>; /* RFA */
		qca,bt-vdd-pa-supply =   <&L22A>; /* CH0 */
		qca,bt-vdd-xtal-supply = <&L13A>; /* XO */

		qca,bt-vdd-io-voltage-level = <1700000 1900000>;
		qca,bt-vdd-core-voltage-level = <1304000 1304000>;
		/*To support 2.85V level for LDO22 at lower SOC level*/
		qca,bt-vdd-pa-voltage-level = <2850000 3312000>;
		qca,bt-vdd-xtal-voltage-level = <1700000 1900000>;

		qca,bt-vdd-io-current-level = <1>; /* LPM/PFM */
		qca,bt-vdd-core-current-level = <1>; /* LPM/PFM */
		qca,bt-vdd-pa-current-level = <1>; /* LPM/PFM */
		qca,bt-vdd-xtal-current-level = <1>; /* LPM/PFM */
	};

	msm_gpu: qcom,kgsl-3d0@5900000 { };

	pdm_pwm0: pdm_pwm0@4700000 {
		reg = <0x4700000 0xc000>;
		clocks = <&gcc GCC_PDM_AHB_CLK>,
			<&gcc GCC_PWM0_XO512_CLK>;
		clock-names =  "pdm_ahb_clk", "pwm_core_clk";
		assigned-clocks = <&gcc GCC_PWM0_XO512_CLK>;
		assigned-clock-rates = <19200000>;
		#pwm-cells = <2>;

		pwm@0 {
			frame-index = <0>;
			frame-offset = <0x1000>;
		};

		pwm@1 {
			frame-index = <1>;
			frame-offset = <0x2000>;
		};

		pwm@2 {
			frame-index = <2>;
			frame-offset = <0x3000>;
		};

		pwm@3 {
			frame-index = <3>;
			frame-offset = <0x4000>;
		};

		pwm@4 {
			frame-index = <4>;
			frame-offset = <0x5000>;
		};

		pwm@5 {
			frame-index = <5>;
			frame-offset = <0x6000>;
		};

		pwm@6 {
			frame-index = <6>;
			frame-offset = <0x7000>;
		};

		pwm@7 {
			frame-index = <7>;
			frame-offset = <0x8000>;
		};

		pwm@8 {
			frame-index = <8>;
			frame-offset = <0x9000>;
		};

		pwm@9 {
			frame-index = <9>;
			frame-offset = <0xa000>;
		};
	};

	qcom,msm_gsi {
		compatible = "qcom,msm_gsi";
	};

	qcom,rmnet-ipa {
		compatible = "qcom,rmnet-ipa3";
		qcom,rmnet-ipa-ssr;
		qcom,ipa-platform-type-msm;
		qcom,ipa-advertise-sg-support;
		qcom,ipa-napi-enable;
	};

	qcom,ipa_fws {
		compatible = "qcom,pil-tz-generic";
		qcom,pas-id = <0xf>;
		qcom,firmware-name = "ipa_fws";
		qcom,pil-force-shutdown;
		memory-region = <&pil_ipa_fw_mem>;
		status = "disabled";
	};

	ipa_hw: qcom,ipa@5800000 {
		compatible = "qcom,ipa";
		reg = <0x5800000 0x34000>,
		      <0x5804000 0x28000>;
		pas-ids = <0xf>;
		qcom,use-gsi-ipa-fw = "scuba_ipa_fws";
		firmware-names = "scuba_ipa_fws";
		memory-regions = <&pil_ipa_fw_mem>;
		reg-names = "ipa-base", "gsi-base";
		interrupts = <GIC_SPI 257 IRQ_TYPE_LEVEL_HIGH>,
			     <GIC_SPI 259 IRQ_TYPE_LEVEL_HIGH>;
		interrupt-names = "ipa-irq", "gsi-irq";
		qcom,ipa-hw-ver = <16>; /* IPA core version = IPAv4.2 */
		qcom,ipa-hw-mode = <0>;
		qcom,ee = <0>;
		qcom,platform-type = <1>; /* MSM platform */
		qcom,use-ipa-tethering-bridge;
		qcom,modem-cfg-emb-pipe-flt;
		qcom,ipa-wdi2;
		qcom,ipa-wdi2_over_gsi;
		qcom,ipa-endp-delay-wa;
		qcom,ipa-fltrt-not-hashable;
		qcom,use-64-bit-dma-mask;
		qcom,arm-smmu;
		qcom,smmu-fast-map;
		qcom,use-ipa-pm;
		qcom,skip-ieob-mask-wa;
		qcom,max_num_smmu_cb = <3>;
		clocks = <&rpmcc RPM_SMD_IPA_CLK>;
		clock-names = "core_clk";
		qcom,interconnect,num-cases = <5>;
		qcom,interconnect,num-paths = <3>;
		interconnects = <&system_noc MASTER_IPA &bimc SLAVE_EBI_CH0>,
				<&system_noc MASTER_IPA &system_noc SLAVE_OCIMEM>,
				<&bimc MASTER_AMPSS_M0 &config_noc SLAVE_IPA_CFG>;
		interconnect-names = "ipa_to_ebi1", "ipa_to_imem", "appss_to_ipa";
		/* No vote */
		qcom,no-vote =
		<0 0 0 0 0 0>;
		/* SVS2 */
		qcom,svs2 =
		<80000 465000 80000 68570 80000 30>;
		/* SVS */
		qcom,svs =
		<80000 2000000 80000 267461 80000 109890>;
		/* NOMINAL */
		qcom,nominal =
		<206000 4000000 206000 712961 206000 491520>;
		/* TURBO */
		qcom,turbo =
		<206000 5598900 206000 1436481 206000 491520>;
		qcom,bus-vector-names =
		"MIN", "SVS2", "SVS", "NOMINAL", "TURBO";
		qcom,throughput-threshold = <310 600 1000>;
		qcom,scaling-exceptions = <>;

		/* smp2p information */
		qcom,smp2p_map_ipa_1_out {
			compatible = "qcom,smp2p-map-ipa-1-out";
			qcom,smem-states = <&smp2p_ipa_1_out 0>;
			qcom,smem-state-names = "ipa-smp2p-out";
		};

		qcom,smp2p_map_ipa_1_in {
			compatible = "qcom,smp2p-map-ipa-1-in";
			interrupts-extended = <&smp2p_ipa_1_in 0 0>;
			interrupt-names = "ipa-smp2p-in";
		};
	};

	ipa_smmu_ap: ipa_smmu_ap {
		compatible = "qcom,ipa-smmu-ap-cb";
		iommus = <&apps_smmu 0x0140 0x0>;
		qcom,iommu-dma-addr-pool = <0x10000000 0x30000000>;
		/* modem tables in IMEM */
		qcom,additional-mapping = <0x0c123000 0x0c123000 0x2000>;
		qcom,iommu-dma = "atomic";
	};

	ipa_smmu_wlan: ipa_smmu_wlan {
		compatible = "qcom,ipa-smmu-wlan-cb";
		iommus = <&apps_smmu 0x141 0x0>;
		/* ipa-uc ram */
		qcom,additional-mapping = <0x5860000 0x5860000 0x80000>;
		qcom,iommu-dma = "atomic";
	};

	ipa_smmu_uc: ipa_smmu_uc {
		compatible = "qcom,ipa-smmu-uc-cb";
		iommus = <&apps_smmu 0x0142 0x0>;
		qcom,iommu-dma-addr-pool = <0x40400000 0x1fc00000>;
	};
};

#include "pm2250.dtsi"
#include "scuba-thermal.dtsi"
#include "scuba-coresight.dtsi"
#include "scuba-pinctrl.dtsi"
#include "scuba-dma-heaps.dtsi"
#include "pm2250-rpm-regulator.dtsi"
#include "scuba-regulator.dtsi"
#include "scuba-gdsc.dtsi"
#include "scuba-qupv3.dtsi"
#include "scuba-usb.dtsi"
#include "msm-arm-smmu-scuba.dtsi"

&qupv3_se1_i2c {
	status = "ok";
	#include "pm8008.dtsi"
};

&pm8008_8 {
	/* PM8008 IRQ STAT */
	interrupt-parent = <&tlmm>;
	interrupts = <25 IRQ_TYPE_EDGE_RISING>;

	pinctrl-names = "default";
	pinctrl-0 = <&pm8008_active &pm8008_interrupt>;
};

&pm8008_regulators {
	vdd_l1_l2-supply = <&S3A>;
};

&L1P {
	regulator-max-microvolt = <1260000>;
	qcom,min-dropout-voltage = <75000>;
};

&L2P {
	regulator-max-microvolt = <1150000>;
	qcom,min-dropout-voltage = <187500>;
};

&L3P {
	regulator-min-microvolt = <2700000>;
	regulator-max-microvolt = <2900000>;
};

&L4P {
	regulator-min-microvolt = <2700000>;
	regulator-max-microvolt = <2900000>;
};

&L5P {
	regulator-min-microvolt = <2700000>;
	regulator-max-microvolt = <2900000>;
};

&L6P {
	regulator-min-microvolt = <2700000>;
	regulator-max-microvolt = <2900000>;
};

&L7P {
	regulator-min-microvolt = <1650000>;
	regulator-max-microvolt = <1900000>;
};

&pm2250_vadc {
	#address-cells = <1>;
	#size-cells = <0>;
	pinctrl-names = "default";
	pinctrl-0 = <&conn_therm_default &skin_therm_default>;

	xo_therm {
		reg = <ADC5_XO_THERM_100K_PU>;
		label = "xo_therm";
		qcom,ratiometric;
		qcom,hw-settle-time = <200>;
		qcom,pre-scaling = <1 1>;
	};

	pa_therm {
		reg = <ADC5_AMUX_THM1_100K_PU>;
		label = "pa_therm";
		qcom,ratiometric;
		qcom,hw-settle-time = <200>;
		qcom,pre-scaling = <1 1>;
	};

	quiet_therm {
		reg = <ADC5_AMUX_THM2_100K_PU>;
		label = "quiet_therm";
		qcom,ratiometric;
		qcom,hw-settle-time = <200>;
		qcom,pre-scaling = <1 1>;
	};

	msm_therm {
		reg = <ADC5_AMUX_THM3_100K_PU>;
		label = "msm_therm";
		qcom,ratiometric;
		qcom,hw-settle-time = <200>;
		qcom,pre-scaling = <1 1>;
	};

	skin_therm {
		reg = <ADC5_GPIO3_100K_PU>;
		label = "skin_therm";
		qcom,ratiometric;
		qcom,hw-settle-time = <200>;
		qcom,pre-scaling = <1 1>;
	};

	conn_therm {
		reg = <ADC5_GPIO4_100K_PU>;
		label = "conn_therm";
		qcom,ratiometric;
		qcom,hw-settle-time = <200>;
		qcom,pre-scaling = <1 1>;
	};
};

&pm2250_gpios {
	skin_therm {
		skin_therm_default: skin_therm_default {
			pins = "gpio5";
			bias-high-impedance;
		};
	};

	conn_therm {
		conn_therm_default: conn_therm_default {
			pins = "gpio6";
			bias-high-impedance;
		};
	};
};

&spmi_bus {
	qcom,pm2250@0 {
		pm2250_adc_tm_iio: adc_tm@3400 {
			compatible = "qcom,spmi-adc-tm5-iio";
			reg = <0x3400>;
			#thermal-sensor-cells = <1>;
			#address-cells = <1>;
			#size-cells = <0>;

			xo_therm {
				reg = <0>;
				io-channels = <&pm2250_vadc ADC5_XO_THERM_100K_PU>;
			};

			pa_therm {
				reg = <1>;
				io-channels = <&pm2250_vadc ADC5_AMUX_THM1_100K_PU>;
			};

			quiet_therm {
				reg = <2>;
				io-channels = <&pm2250_vadc ADC5_AMUX_THM2_100K_PU>;
			};

			msm_therm {
				reg = <3>;
				io-channels = <&pm2250_vadc ADC5_AMUX_THM3_100K_PU>;
			};

			skin_therm {
				reg = <4>;
				io-channels = <&pm2250_vadc ADC5_GPIO3_100K_PU>;
			};

			conn_therm {
				reg = <5>;
				io-channels = <&pm2250_vadc ADC5_GPIO4_100K_PU>;
			};

			s3_die_temp {
				reg = <6>;
				io-channels = <&pm2250_vadc ADC5_SBUx>;
			};
		};
	};
};

&gcc_camss_top_gdsc {
	status = "ok";
};

&gcc_usb30_prim_gdsc {
	status = "ok";
};

&gcc_vcodec0_gdsc {
	qcom,support-hw-trigger;
	status = "ok";
};

&gcc_venus_gdsc {
	status = "ok";
};

&hlos1_vote_mm_snoc_mmu_tbu_rt_gdsc {
	status = "ok";
};

&hlos1_vote_mm_snoc_mmu_tbu_nrt_gdsc {
	status = "ok";
};

&hlos1_vote_turing_mmu_tbu1_gdsc {
	status = "ok";
};

&hlos1_vote_turing_mmu_tbu0_gdsc {
	status = "ok";
};

&mdss_core_gdsc {
	qcom,support-hw-trigger;
	status = "ok";
};

&gpu_cx_gdsc {
	status = "ok";
};

&gpu_gx_gdsc {
	status = "ok";
};

&qupv3_se4_2uart {
	status = "ok";
};

&qupv3_se3_4uart {
	status = "ok";
};

&soc {
	gpio_keys {
		compatible = "gpio-keys";
		label = "gpio-keys";
		pinctrl-names = "default";
		pinctrl-0 = <&gpio_vol_up>;

		vol_up {
			label = "vol_up";
			gpios = <&tlmm 96 GPIO_ACTIVE_LOW>;
			linux,input-type = <1>;
			linux,code = <KEY_VOLUMEUP>;
			debounce-interval = <15>;
			linux,can-disable;
		};
	};
};

#include "msm-rdbg-scuba.dtsi"
